# TOP_RCM_TOP_RCM_53200000h register map
Vendor: Texas Instruments
Registers are 32-bit, read-write, reset 0x0 unless marked. A register's access mark holds for its fields unless they carry their own. Offsets are as the file gives them; [hi:lo] are bit positions; {n}, {i} and the like mark numbered series.

## TOP_RCM (part 2 of 2)
0x04 TOP_RCM_SYS_RST_CAUSE ro reset 0x41 — Warm Reset Cause Register.
  [26:0] SYS_RST_CAUSE_CAUSE — Warm Reset Cause register 27'h0000041 - POR reset 27'h0000042 - Warm reset due to MSS_WDT0 27'h0000044 - Warm reset due to MSS_WDT1 27'h0000060 - Warm reset due to TOP_RMC:WARM_RESET_REQ 27'h0000040 - External Pad reset 27'h00000c0 - Warm reset due to HSM_WDT 27'h0000140 - Warm Reset due to Debugger reset 27'h0000240 - Warm Reset due to Temp Sense0 Reset 27'h0000440 - Warm Reset due to Temp Sense1 Reset 27'h0000840 - Warm Reset due to vmon_cmp1_ov 27'h0001040 - Warm Reset due to vmon_cmp2_ov 27'h0002040 - Warm Reset due to vmon_cmp3_ov 27'h0004040 - Warm Reset due to vmon_cmp5_ov 27'h0008040 - Warm Reset due to vmon_cmp0_uv 27'h0010040 - Warm Reset due to vmon_cmp1_uv 27'h0020040 - Warm Reset due to vmon_cmp2_uv 27'h0040040 - Warm Reset due to vmon_cmp3_uv 27'h0080040 - Warm Reset due to vmon_cmp5_uv 27'h0100040 - Warm Reset due to vmon_cmp7_uv 27'h0200040 - Warm Reset due to vmon_cmp8_uv 27'h0400040 - Warm Reset due to clk_loss on sys_clk 27'h0800040 - Warm Reset due to esm critical priority interrupt27'h1000040 - Warm Reset due to esm high priority watchdog interrupt27'h2000040 - Warm Reset due to esm error pin monitor interrupt 27'h4000040 - POR assert from SW
0x08 TOP_RCM_SYS_RST_CAUSE_CLR — Warm Reset Cause Register Clear.
  [2:0] SYS_RST_CAUSE_CLR_CLEAR — Write pulse bit field to 3'b111: Data should be loaded as multibit. Warm Reset Cause register Clear
0x0C TOP_RCM_WARM_RESET_REQ reset 0x7 — Warm Reset Config options.
  [2:0] WARM_RESET_REQ_SW_RST — Data should be loaded as multibit. Write 3'b000 to assert warm reset from SWWrite 3'b111 to deassert warm reset from SW if this is the only source of warm reset
0x10 TOP_RCM_WARM_RSTTIME1 reset 0x888 — programing Output delay: time between internal warm reset source assert to warm reset pad deassert.
  [11:0] WARM_RSTTIME1_DELAY — Program sufficient delay using this bitfield to keep the WARMRSTn pad active for any external devices relying on the reset signal. Refer to Reset Details Section in TRM for more details.Data should be loaded as multibit. For example: if value of 0x5 should be selected then 0x555 should be configured to the register.**Note: This bit will only be reset by PORz.
0x14 TOP_RCM_WARM_RSTTIME2 reset 0x888 — programing input Rise delay : time between warm reset pad deassert to chip warm reset deassert.
  [11:0] WARM_RSTTIME2_DELAY — Program the deassertion delay with this bitfield to control internal system reset deassertion which is relative to the deassertion of WARMRSTn pad.Data should be loaded as multibit. For example: if value of 0x5 should be selected then 0x555 should be configured to the register.**Note: This bit will only be reset by PORz.
0x18 TOP_RCM_WARM_RSTTIME3 reset 0x111 — programing Input Fall delay : time between warm reset pad assert to chip warm reset assert.
  [11:0] WARM_RSTTIME3_DELAY — The glitch filter logic will filter any input pad signal which is LOW for any time less than the delay programmed with this bit.This parameter also programmes the delay from external Warmrestn assertion to Internal system warm resetn assertion.Data should be loaded as multibit. For example: if value of 0x5 should be selected then 0x555 should be configured to the register.**Note: This bit will only be reset by PORz.
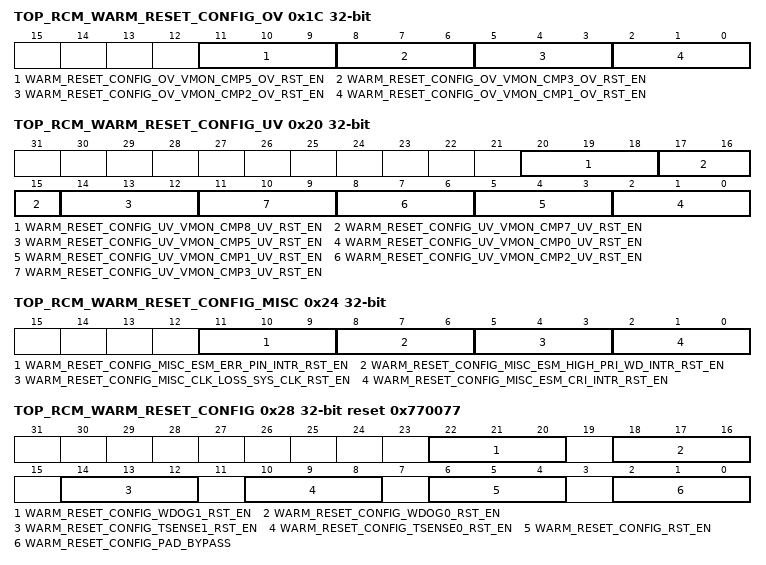
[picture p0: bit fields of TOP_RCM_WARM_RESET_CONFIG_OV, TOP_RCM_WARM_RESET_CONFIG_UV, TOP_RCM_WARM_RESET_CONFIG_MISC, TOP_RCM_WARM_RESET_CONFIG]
0x1C TOP_RCM_WARM_RESET_CONFIG_OV — VMON OverVoltage triggering Warm Reset Config.
  [11:9] WARM_RESET_CONFIG_OV_VMON_CMP5_OV_RST_EN — Enable/Disable VMON Overvoltage CMP5 triggering Warm ResetData should be loaded as multibit. Write 3'b000 to disable vmon_ov rst_en Write 3'b111 to enable vmon_ov rst_en **Note: This bit will only be reset by PORz.
  [8:6] WARM_RESET_CONFIG_OV_VMON_CMP3_OV_RST_EN — Enable/Disable VMON Overvoltage CMP3 triggering Warm ResetData should be loaded as multibit. Write 3'b000 to disable vmon_ov rst_en Write 3'b111 to enable vmon_ov rst_en **Note: This bit will only be reset by PORz.
  [5:3] WARM_RESET_CONFIG_OV_VMON_CMP2_OV_RST_EN — Enable/Disable VMON Overvoltage CMP2 triggering Warm ResetData should be loaded as multibit. Write 3'b000 to disable vmon_ov rst_en Write 3'b111 to enable vmon_ov rst_en **Note: This bit will only be reset by PORz.
  [2:0] WARM_RESET_CONFIG_OV_VMON_CMP1_OV_RST_EN — Enable/Disable VMON Overvoltage CMP1 triggering Warm ResetData should be loaded as multibit. Write 3'b000 to disable vmon_ov rst_en Write 3'b111 to enable vmon_ov rst_en**Note: This bit will only be reset by PORz.
0x20 TOP_RCM_WARM_RESET_CONFIG_UV — VMON UnderVoltage triggering Warm Reset Config.
  [20:18] WARM_RESET_CONFIG_UV_VMON_CMP8_UV_RST_EN — Enable/Disable VMON Undervoltage CMP8 triggering Warm ResetData should be loaded as multibit. Write 3'b000 to disable vmon_uv rst_en Write 3'b111 to enable vmon_uv rst_en **Note: This bit will only be reset by PORz.
  [17:15] WARM_RESET_CONFIG_UV_VMON_CMP7_UV_RST_EN — Enable/Disable VMON Undervoltage CMP7 triggering Warm ResetData should be loaded as multibit. Write 3'b000 to disable vmon_uv rst_en Write 3'b111 to enable vmon_uv rst_en **Note: This bit will only be reset by PORz.
  [14:12] WARM_RESET_CONFIG_UV_VMON_CMP5_UV_RST_EN — Enable/Disable VMON Undervoltage CMP5 triggering Warm ResetData should be loaded as multibit. Write 3'b000 to disable vmon_uv rst_en Write 3'b111 to enable vmon_uv rst_en **Note: This bit will only be reset by PORz.
  [3n+2:3n] WARM_RESET_CONFIG_UV_VMON_CMP{n}_UV_RST_EN (n=0..3) — Enable/Disable VMON Undervoltage CMP{n} triggering Warm ResetData should be loaded as multibit. Write 3'b000 to disable vmon_uv rst_en Write 3'b111 to enable vmon_uv rst_en **Note: This bit will only be reset by PORz.
0x24 TOP_RCM_WARM_RESET_CONFIG_MISC — ESM and Clk Loss on SYS_CLK triggering Warm Reset Config.
  [11:9] WARM_RESET_CONFIG_MISC_ESM_ERR_PIN_INTR_RST_EN — Enable/Disable ESM triggering Warm ResetData should be loaded as multibit. Write 3'b000 to disable esm rst_en Write 3'b111 to enable esm rst_en
  [8:6] WARM_RESET_CONFIG_MISC_ESM_HIGH_PRI_WD_INTR_RST_EN — Enable/Disable ESM triggering Warm ResetData should be loaded as multibit. Write 3'b000 to disable esm rst_en Write 3'b111 to enable esm rst_en
  [5:3] WARM_RESET_CONFIG_MISC_CLK_LOSS_SYS_CLK_RST_EN — Enable/Disable Clock loss on SYS_CLK triggering Warm ResetData should be loaded as multibit. Write 3'b000 to disable clk_loss on sys_clk rst_en Write 3'b111 to enable clk_loss on sys_clk rst_en
  [2:0] WARM_RESET_CONFIG_MISC_ESM_CRI_INTR_RST_EN — Enable/Disable ESM triggering Warm ResetData should be loaded as multibit. Write 3'b000 to disable esm rst_en Write 3'b111 to enable esm rst_en
0x28 TOP_RCM_WARM_RESET_CONFIG reset 0x770077 — Warm Reset Config options.
  [22:20] WARM_RESET_CONFIG_WDOG1_RST_EN — Enable/Disable WATCHDOG1 triggering Warm ResetData should be loaded as multibit. Write 3'b000 to disable corresponding Watchdog Write 3'b111 enable corresponding Watchdog
  [18:16] WARM_RESET_CONFIG_WDOG0_RST_EN — Enable/Disable WATCHDOG0 triggering Warm ResetData should be loaded as multibit. Write 3'b000 to disable corresponding Watchdog Write 3'b111 enable corresponding Watchdog
  [14:12] WARM_RESET_CONFIG_TSENSE1_RST_EN — Enable/Disable TEMPSENSE1 triggering Warm ResetData should be loaded as multibit. Write 3'b000 to disable temperature sensor 1 Write 3'b111 to enable temperature sensor 1 **Note: This bit will only be reset by PORz.
  [10:8] WARM_RESET_CONFIG_TSENSE0_RST_EN — Enable/Disable TEMPSENSE0 triggering Warm ResetData should be loaded as multibit. Write 3'b000 to disable temperature sensor 0 Write 3'b111 to enable temperature sensor 0 **Note: This bit will only be reset by PORz.
  [6:4] WARM_RESET_CONFIG_RST_EN — Enable/Disable DEBUGSS triggering Warm ResetData should be loaded as multibit. Write 3'b000 to disable debugger control on Warm ResetWrite 3'b111 enable debugger control on Warm Reset
  [2:0] WARM_RESET_CONFIG_PAD_BYPASS — Bypass the Warm reset from Pad InputData should be loaded as multibit. Write 3'b000 : Pad Warm Reset pin has control over warm resetWrite 3'b111 : Pad warm reset pin has no control on warm reset**Note: This bit will only be reset by PORz.
0x2C TOP_RCM_SW_POR — To trigger POR through software .
  [2:0] SW_POR_ASSERT — Software POR triggerData should be loaded as multibitWrite 3'b000: Reset is not asserted by SWWrite 3'b111: Reset is asserted by SW
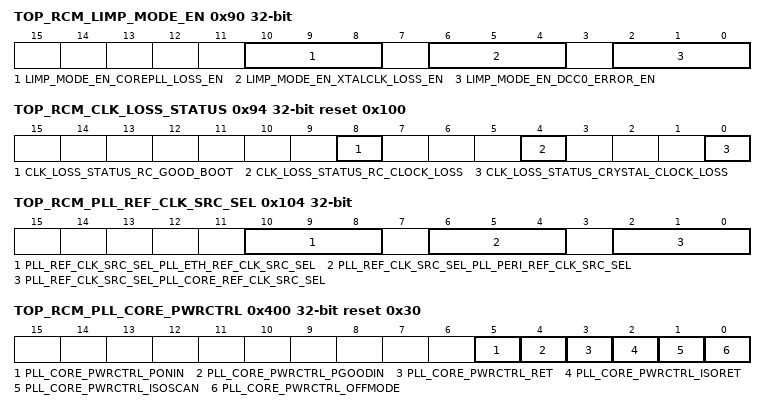
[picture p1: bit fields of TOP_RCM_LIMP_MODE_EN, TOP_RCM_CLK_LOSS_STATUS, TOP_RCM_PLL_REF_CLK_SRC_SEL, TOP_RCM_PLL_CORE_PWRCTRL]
0x90 TOP_RCM_LIMP_MODE_EN — LIMP_MODE_EN.
  [10:8] LIMP_MODE_EN_COREPLL_LOSS_EN — Enable for core pll phase lock loss to generate Limp mode3'b000: will not generate Limp mode [multibit 000]3'b111 : will generate Limp mode [multibit 111]
  [6:4] LIMP_MODE_EN_XTALCLK_LOSS_EN — Enable for crystal_clock_loss to generate Limp mode3'b000: will not generate Limp mode [multibit 000]3'b111 : will generate Limp mode [multibit 111]
  [2:0] LIMP_MODE_EN_DCC0_ERROR_EN — Enable DCC0 Error to generate Limp mode 3'b000: DCC0 Error will not generate Limp mode [multibit 000]3'b111 : DCC0 Error will generate Limp mode [multibit 111]
0x94 TOP_RCM_CLK_LOSS_STATUS ro reset 0x100 — Coarse detection clock loss status for RC and Crystal.
  [8] CLK_LOSS_STATUS_RC_GOOD_BOOT — Clock status of RC clock at boot. Reset value will reflect the actual status1 --> clock present at boot0 --> clock not present at boot
  [4] CLK_LOSS_STATUS_RC_CLOCK_LOSS — Coarse detection clock loss status for RC clock. Reset value will reflect the actual status1 --> clock lost0 --> clock good
  [0] CLK_LOSS_STATUS_CRYSTAL_CLOCK_LOSS — Coarse detection clock loss status for Crystal clock. Reset value will reflect the actual status1 --> clock lost0 --> clock good
0x100 TOP_RCM_RCOSC32K_CTRL — RCOSC32K_CTRL.
  [2:0] RCOSC32K_CTRL_STOPOSC — Stop 32KHz RCOSC. Write 3'b111 to stop clock
0x104 TOP_RCM_PLL_REF_CLK_SRC_SEL — CORE PLL and PERI PLL reference clock select.
  [10:8] PLL_REF_CLK_SRC_SEL_PLL_ETH_REF_CLK_SRC_SEL — Mux selct for PERI PLL1 REF clockWrite 3'b111 : to select external reference clock as PLL reference clockWrite 3'b000 : to select on-die clock as PLL reference clock
  [6:4] PLL_REF_CLK_SRC_SEL_PLL_PERI_REF_CLK_SRC_SEL — Mux selct for PERI PLL REF clockWrite 3'b111 : to select external reference clock as PLL reference clockWrite 3'b000 : to select on-die clock as PLL reference clock
  [2:0] PLL_REF_CLK_SRC_SEL_PLL_CORE_REF_CLK_SRC_SEL — Mux selct for CORE PLL REF clockWrite 3'b111 : to select external reference clock as PLL reference clockWrite 3'b000 : to select on-die clock as PLL reference clock
0x10C TOP_RCM_SOP_MODE_VALUE ro — SOP_MODE_VALUE.
  [31:0] SOP_MODE_VALUE_VAL — Bootmode (SOP_MODE) values and their corresponding mapping SOP3 SOP2 SOP1 SOP0 Bootmode 0 0 0 0 OSPI Functional Mode[4S] 0 0 0 1 UART Functional Mode 0 0 1 0 OSPI Functional Mode[1S] 0 0 1 1 OSPI Functional Mode[8S] 0 1 1 0 OSPI Serial NAND Functional Mode[1S] 0 1 1 1 OSPI Serial NAND Functional Mode[4S] 1 0 1 1 DevBoot mode 1 1 0 0 xSPI 8D (SFDP)mode 1 1 0 1 OSPI Serial NAND (8S) mode 1 1 1 0 USB DFU mode Any undefined values are reserved for future use.Note: Reset value of MMR is 0, but true SOP pin values will latch immediately after PORz reset is released. CPU reads to the MMR will only reflect the SOP mode values latched at reset.
0x114 TOP_RCM_VMON_CLK_GATE — VMON_CLK_GATE.
  [2:0] VMON_CLK_GATE_ENABLE — Clock gatring config for VMON clockData should be loaded as multibit. Write 3'b000 : Clock is ungated [multibit 000]Write 3'b111 : Clock is gated [multibit 111]
0x400 TOP_RCM_PLL_CORE_PWRCTRL reset 0x30 — PLL_CORE_PWRCTRL refer to PLL spec for complete functional description of the below bitfields.
  [5] PLL_CORE_PWRCTRL_PONIN — ON/OFF control of the weak power switch digital. For functionalmode it should be 1'b1
  [4] PLL_CORE_PWRCTRL_PGOODIN — ON/OFF control of the strong power switch digital. For functional mode it should be 1'b1
  [3] PLL_CORE_PWRCTRL_RET — Save/Restore control for Retention mode. For functional mode itshould be 1'b0
  [2] PLL_CORE_PWRCTRL_ISORET — Save/Restore control for Isolation of output pins For functional modeit should be 1'b0
  [1] PLL_CORE_PWRCTRL_ISOSCAN — Save/Restore control for Isolation of the Scanout pins. For functionalmode it should be 1'b0
  [0] PLL_CORE_PWRCTRL_OFFMODE — Used to switch OFF the logic on VDDA. For functional mode itshould be 1'b0
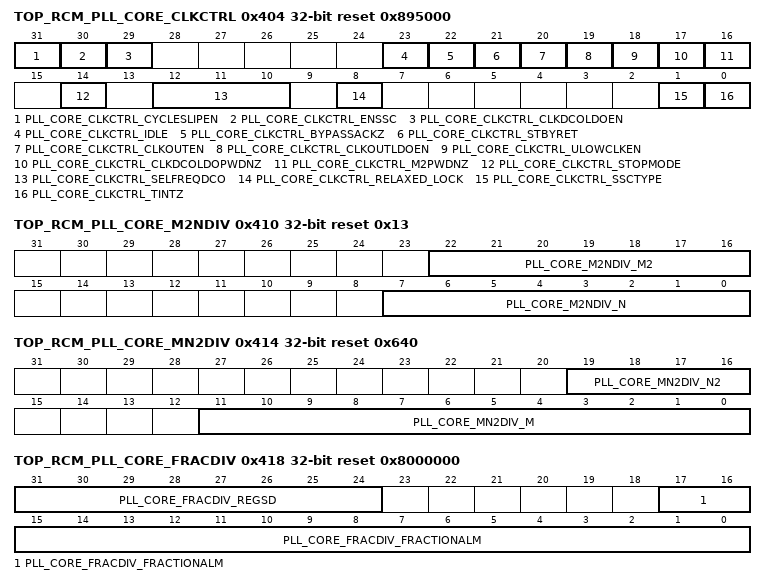
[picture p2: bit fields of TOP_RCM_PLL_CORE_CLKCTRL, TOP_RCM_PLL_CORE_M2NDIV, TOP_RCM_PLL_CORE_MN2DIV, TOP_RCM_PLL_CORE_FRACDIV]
0x404 TOP_RCM_PLL_CORE_CLKCTRL reset 0x895000 — PLL_CORE_CLKCTRL refer to PLL spec for complete functional description of the below bitfields.
  [31] PLL_CORE_CLKCTRL_CYCLESLIPEN — FailSafe enable to trigger re-calibration in case CycleSlip occurs between REFCLK and FBCLK. Cycleslip could be caused if loop is not able to track input clock. Default = 1'b0 recommended
  [30] PLL_CORE_CLKCTRL_ENSSC — Controls Clock SpReading. SSC is not supported. Should be set to 0x0 to disable clock spReading.
  [29] PLL_CORE_CLKCTRL_CLKDCOLDOEN — Synchronously enables/disables CLKDCOLDO0x0 : synchronously disables CLKDCOLDO0x1 : synchronously enables CLKDCOLDO
  [23] PLL_CORE_CLKCTRL_IDLE — Sets PLL to Idle mode0x0 : When SYSRESET = 0 and TINITZ = 1 IDLE = 0 PLL will go toActive and Locked0x1 : When SYSRESET = 0 and TINITZ = 1 IDLE = 1 PLL will go toIdle Bypass low powe
  [22] PLL_CORE_CLKCTRL_BYPASSACKZ — BYPASSACKZ is a special purpose input to the module. In generalthis input is expected to be tied to static low. For the output clocks ofthe module that do not have an internal bypass mux viz.CLKDCOLDO and CLKOUTLDO, a bypass mux could beimplemented external to the module.
  [21] PLL_CORE_CLKCTRL_STBYRET — Standby retention control0x0 : prepares ADPLLLJ for relock when out of retention byremoving the gating on all internal clocks.0x1 : prepares ADPLLLJ for retention by gating all the internalclocks.
  [20] PLL_CORE_CLKCTRL_CLKOUTEN — CLKOUT enable or disable0x0 : synchronously disables CLKOUT0x1 : synchronously enables CLKOUT
  [19] PLL_CORE_CLKCTRL_CLKOUTLDOEN — Synchronously enables/disables CLKOUTLDO 0x0 : synchronously disables CLKOUTLDO 0x1 : synchronously enables CLKOUTLDO
  [18] PLL_CORE_CLKCTRL_ULOWCLKEN — Select CLKOUT source in bypass0x0: When ADPLLLJ in bypass mode, CLKOUT = CLKINP/[N2+1]0x1: When ADPLLLJ in bypass mode, CLKOUT = CLKINPULOW.
  [17] PLL_CORE_CLKCTRL_CLKDCOLDOPWDNZ — 0 Asynchronous power down for CLKDCOLDO o/p.
  [16] PLL_CORE_CLKCTRL_M2PWDNZ — M2 divider power down mode0x0: Asynchronous power down for M2 divider0x1 : M2 divider is functional
  [14] PLL_CORE_CLKCTRL_STOPMODE — When in Lossclk/Stbyret 0x0 : Limp mode 0x1 : Stopmode
  [12:10] PLL_CORE_CLKCTRL_SELFREQDCO — DCO Clock [DCOCLK = CLKINP * [M/[N+1]]] frequency rangeselector.0x0: Reserved0x2: HS2 : DCOCLK range is from 500 MHz to1000MHz0x3: Reserved0x4: HS1: DCOCLK range is from1000MHz to2000MHz0x5: Reserved
  [8] PLL_CORE_CLKCTRL_RELAXED_LOCK — Decides when FREQLOCK asserted0x0: FREQLOCK asserted when DC frequency error less than 1%0x1: FREQLOCK asserted when DC frequency error less than 2%
  [1] PLL_CORE_CLKCTRL_SSCTYPE — SSC Type - This should be configured as 1'b0. The module supports spread spectrum clocking [SSC] on its output clocks.
  [0] PLL_CORE_CLKCTRL_TINTZ — PLL core soft reset. TINITZ activation [Low] gives softreset to ADPLLLJ. TINITZ does not reset the entire digital control logic; it forces the FSM into RESET State so that ADPLLLJ could restart.
0x408 TOP_RCM_PLL_CORE_TENABLE — PLL_CORE_TENABLE refer to PLL spec for complete functional description of the below bitfields.
  [0] PLL_CORE_TENABLE_TENABLE — Signal TENABLE loads REGM, REGN, REGSD and SELFREQDCO data. M, N. SD and SELFREQDCO latch [active rise edge]
0x40C TOP_RCM_PLL_CORE_TENABLEDIV — PLL_CORE_TENABLEDIV refer to PLL spec for complete functional description of the below bitfields.
  [0] PLL_CORE_TENABLEDIV_TENABLEDIV — TENABLEDIV rising edge loads the values of M2REG and N2REG into ADPLLLJ register. TENABLEDIV could be activated anytime when the DPLL digital is in power-up condition. M2 and N2 latch [active rise edge]
0x410 TOP_RCM_PLL_CORE_M2NDIV reset 0x13 — PLL_CORE_M2NDIV refer to PLL spec for complete functional description of the below bitfields.
  [22:16] PLL_CORE_M2NDIV_M2 — Post-divider is REGM2
  [7:0] PLL_CORE_M2NDIV_N — Pre-divider is REGN+1
0x414 TOP_RCM_PLL_CORE_MN2DIV reset 0x640 — PLL_CORE_MN2DIV refer to PLL spec for complete functional description of the below bitfields.
  [19:16] PLL_CORE_MN2DIV_N2 — Bypass divider is REGN2+1
  [11:0] PLL_CORE_MN2DIV_M — Feedback Multiplier is REGM
0x418 TOP_RCM_PLL_CORE_FRACDIV reset 0x8000000 — PLL_CORE_FRACDIV refer to PLL spec for complete functional description of the below bitfields.
  [31:24] PLL_CORE_FRACDIV_REGSD — Sigma-Delta DividerShould be set by s/w to provide optimum jitter performance.DPLL_SD_DIV = CEILING [[DPLL_MULT/[DPLL_DIV+1]] * CLKINP/ 250], where CLKINP is the input clock of the DPLL in MHz
  [17:0] PLL_CORE_FRACDIV_FRACTIONALM — Fractional part of the M divider.The 18bit FractionalM value is loaded into DPLL on the rising edge of TENABLE signal .To enable Integer only division FractionalM should be set to 18'b0.
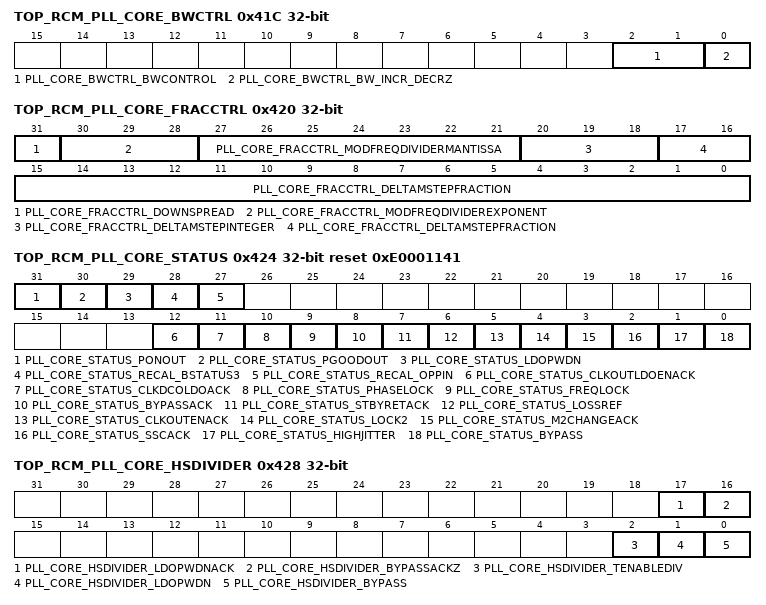
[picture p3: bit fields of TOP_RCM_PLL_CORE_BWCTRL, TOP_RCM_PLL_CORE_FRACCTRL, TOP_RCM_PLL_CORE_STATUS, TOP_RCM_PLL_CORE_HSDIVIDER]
0x41C TOP_RCM_PLL_CORE_BWCTRL — PLL_CORE_BWCTRL refer to PLL spec for complete functional description of the below bitfields.
  [2:1] PLL_CORE_BWCTRL_BWCONTROL — Change Loop Bandwidth
  [0] PLL_CORE_BWCTRL_BW_INCR_DECRZ — Direction of Loop Bandwidth0x0 : decrease BW0x1 : increase BW
0x420 TOP_RCM_PLL_CORE_FRACCTRL — PLL_CORE_FRACCTRL refer to PLL spec for complete functional description of the below bitfields.
  [31] PLL_CORE_FRACCTRL_DOWNSPREAD — Controls frequency spread0x0 : enables both side frequency spread about the programmed frequency.0x1 : enables low frequency spread only
  [30:28] PLL_CORE_FRACCTRL_MODFREQDIVIDEREXPONENT — Exponent of the REFCLK divider to define the modulation frequency.
  [27:21] PLL_CORE_FRACCTRL_MODFREQDIVIDERMANTISSA — Mantissa of the REFCLK divider to define the modulation frequency
  [20:18] PLL_CORE_FRACCTRL_DELTAMSTEPINTEGER — Integer part of Frequency Spread control
  [17:0] PLL_CORE_FRACCTRL_DELTAMSTEPFRACTION — The fraction part of Frequency Spread control
0x424 TOP_RCM_PLL_CORE_STATUS ro reset 0xE0001141 — PLL_CORE_STATUS refer to PLL spec for complete functional description of the below bitfields.
  [31] PLL_CORE_STATUS_PONOUT — Status of the weak power-switch0x0 : indicates the/OFF status of the weak power-switch in digital toSOC.0x1 : ndicates the ON status of the weak power-switch in digital toSOC.
  [30] PLL_CORE_STATUS_PGOODOUT — Status of the strong power-switch0x0 : indicates the/OFF status of the strong power-switch in digital toSOC.0x1 : ndicates the ON status of the strong power-switch in digital toSOC.
  [29] PLL_CORE_STATUS_LDOPWDN — 1'b1 indicates ADPLLLJ internal LDO is power down. VDDLDOOUT willbe un-defined in this condition
  [28] PLL_CORE_STATUS_RECAL_BSTATUS3 — Recalibration status flag. 1'b1 ADPLLLJ requires recalibration
  [27] PLL_CORE_STATUS_RECAL_OPPIN — Recalibration status flag. 1'b1 ADPLLLJ requires recalibration
  [12] PLL_CORE_STATUS_CLKOUTLDOENACK — Indicates the enable/disable condition of CLKOUTLDOEN0x0 = CLKOUTLDO gating completed0x1 = CLKOUTLDO enabling completed
  [11] PLL_CORE_STATUS_CLKDCOLDOACK — Indicates the enable/disable condition of CLKDCOLDOEN0x0 = CLKDCOLDO gating completed0x1 = CLKDCOLOD enabling completed
  [10] PLL_CORE_STATUS_PHASELOCK — Status on PHASELOCK output pin
  [9] PLL_CORE_STATUS_FREQLOCK — Status on FREQLOCK output pin
  [8] PLL_CORE_STATUS_BYPASSACK — Status of BYPASSACK output pin
  [7] PLL_CORE_STATUS_STBYRETACK — Standby and retention status0x0: indicates to SOC that all internal clocks in ADPLLLJ are activeand it is starting the relock process.0x1: indicates to SOC that all internal clocks in ADPLLLJ are gatedand it is ready for retention.
  [6] PLL_CORE_STATUS_LOSSREF — Reference input loss is indicated by 1'b0.
  [5] PLL_CORE_STATUS_CLKOUTENACK — Indicates the enable/disable condition of CLKOUTEN0x0 = CLKOUT gating completed0x1 = CLKOUT enabling completed
  [4] PLL_CORE_STATUS_LOCK2 — ADPLL internal loop lock status
  [3] PLL_CORE_STATUS_M2CHANGEACK — Acknowledge for change to M2 divider. Toggles from 1-0 or 0-1[depending on current value] once CLKOUT frequency change hascompleted.
  [2] PLL_CORE_STATUS_SSCACK — Spread Spectrum status0x0 : Spread-spectrum Clocking is disabled on output clocks0x1 : Spread-spectrum Clocking is enabled on output clocks
  [1] PLL_CORE_STATUS_HIGHJITTER — 1'b1 indicates jitter. After PHASELOCK is asserted high, theHIGHJITTER flag is asserted high if phase error between REFCLKand FBCLK greater than 24%.
  [0] PLL_CORE_STATUS_BYPASS — Bypass status signal. 1'b1 CLKOUT in bypass
0x428 TOP_RCM_PLL_CORE_HSDIVIDER access per field — PLL_CORE_HSDIVIDER refer to HSDIVIDER spec for complete functional description of the below bitfields.
  [17] PLL_CORE_HSDIVIDER_LDOPWDNACK ro — LDO Power Down Ack
  [16] PLL_CORE_HSDIVIDER_BYPASSACKZ ro — HSDIVIDER Bypass Ack
  [2] PLL_CORE_HSDIVIDER_TENABLEDIV rw — TENABLEDIV rising edge loads the values of M2REG and N2REG into ADPLLLJ register. TENABLEDIV could be activated anytime when the DPLL digital is in power-up condition. M2 and N2 latch [active rise edge]
  [1] PLL_CORE_HSDIVIDER_LDOPWDN rw — 1'b1 indicates ADPLLLJ internal LDO is power down. VDDLDOOUT willbe un-defined in this condition
  [0] PLL_CORE_HSDIVIDER_BYPASS rw — HSDIVIDER Bypass. Set it to 1'b1 to bypass the HSDIVIDER.
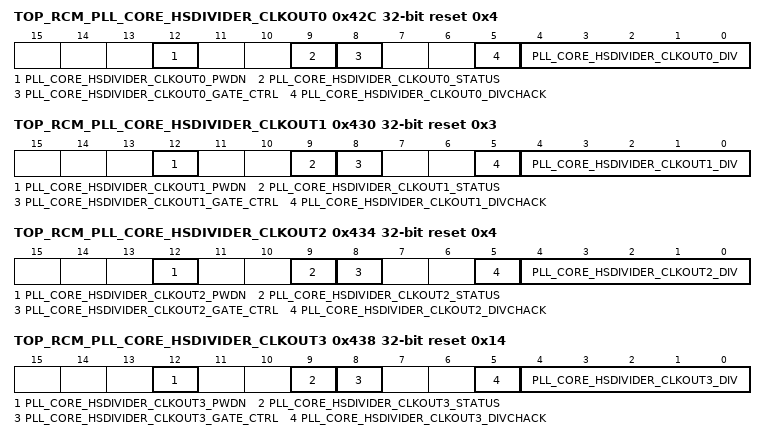
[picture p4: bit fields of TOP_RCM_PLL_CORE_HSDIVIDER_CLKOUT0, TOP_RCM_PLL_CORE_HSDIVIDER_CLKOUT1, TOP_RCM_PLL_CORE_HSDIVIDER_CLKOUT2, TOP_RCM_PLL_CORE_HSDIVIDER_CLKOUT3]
0x42C TOP_RCM_PLL_CORE_HSDIVIDER_CLKOUT0 access per field reset 0x4 — PLL_CORE_HSDIVIDER_CLKOUT0 refer to HSDIVIDER spec for complete functional description of the below bitfields.
  [12] PLL_CORE_HSDIVIDER_CLKOUT0_PWDN rw — Power down for HSDIVIDER CLKOUT0 divider and hence CLKOUT0 output0h[R/W] = CLKOUT0 divider active1h[R/W] = CLKOUT0 divider is powered down
  [9] PLL_CORE_HSDIVIDER_CLKOUT0_STATUS ro — HSDIVIDER CLKOUT0 status0h[R] = The clock output is gated1h[R] = The clock output is enabled
  [8] PLL_CORE_HSDIVIDER_CLKOUT0_GATE_CTRL rw — Control gating of HSDIVIDER CLKOUT00h[R/W] = Automatically gate this clock when there is nodependency for it1h[R/W] = Force this clock to stay enabled even if there is norequest
  [5] PLL_CORE_HSDIVIDER_CLKOUT0_DIVCHACK ro — Toggle on this status bit after changing HSDIVIDER_CLKOUT0_DIVindicates that the change in divider value has taken effect
  [4:0] PLL_CORE_HSDIVIDER_CLKOUT0_DIV rw — DPLL post-divider factor, HSDIVIDER CLKOUT0, for internal clock generation.Divide values from 1 to 31.0h[R/W] = Reserved
0x430 TOP_RCM_PLL_CORE_HSDIVIDER_CLKOUT1 access per field reset 0x3 — PLL_CORE_HSDIVIDER_CLKOUT1 refer to HSDIVIDER spec for complete functional description of the below bitfields.
  [12] PLL_CORE_HSDIVIDER_CLKOUT1_PWDN rw — Power down for HSDIVIDER CLKOUT1 divider and hence CLKOUT1 output0h[R/W] = CLKOUT1 divider active1h[R/W] = CLKOUT1 divider is powered down
  [9] PLL_CORE_HSDIVIDER_CLKOUT1_STATUS ro — HSDIVIDER CLKOUT1 status0h[R] = The clock output is gated1h[R] = The clock output is enabled
  [8] PLL_CORE_HSDIVIDER_CLKOUT1_GATE_CTRL rw — Control gating of HSDIVIDER CLKOUT10h[R/W] = Automatically gate this clock when there is nodependency for it1h[R/W] = Force this clock to stay enabled even if there is norequest
  [5] PLL_CORE_HSDIVIDER_CLKOUT1_DIVCHACK ro — Toggle on this status bit after changing HSDIVIDER_CLKOUT1_DIVindicates that the change in divider value has taken effect
  [4:0] PLL_CORE_HSDIVIDER_CLKOUT1_DIV rw — DPLL post-divider factor, HSDIVIDER CLKOUT1, for internal clock generation.Divide values from 1 to 31.0h[R/W] = Reserved
0x434 TOP_RCM_PLL_CORE_HSDIVIDER_CLKOUT2 access per field reset 0x4 — PLL_CORE_HSDIVIDER_CLKOUT2 refer to HSDIVIDER spec for complete functional description of the below bitfields.
  [12] PLL_CORE_HSDIVIDER_CLKOUT2_PWDN rw — Power down for HSDIVIDER CLKOUT2 divider and hence CLKOUT2 output0h[R/W] = CLKOUT2 divider active1h[R/W] = CLKOUT2 divider is powered down
  [9] PLL_CORE_HSDIVIDER_CLKOUT2_STATUS ro — HSDIVIDER CLKOUT2 status0h[R] = The clock output is gated1h[R] = The clock output is enabled
  [8] PLL_CORE_HSDIVIDER_CLKOUT2_GATE_CTRL rw — Control gating of HSDIVIDER CLKOUT20h[R/W] = Automatically gate this clock when there is nodependency for it1h[R/W] = Force this clock to stay enabled even if there is norequest
  [5] PLL_CORE_HSDIVIDER_CLKOUT2_DIVCHACK ro — Toggle on this status bit after changing HSDIVIDER_CLKOUT2_DIVindicates that the change in divider value has taken effect
  [4:0] PLL_CORE_HSDIVIDER_CLKOUT2_DIV rw — DPLL post-divider factor, HSDIVIDER CLKOUT2, for internal clock generation.Divide values from 1 to 31.0h[R/W] = Reserved
0x438 TOP_RCM_PLL_CORE_HSDIVIDER_CLKOUT3 access per field reset 0x14 — PLL_CORE_HSDIVIDER_CLKOUT3 refer to HSDIVIDER spec for complete functional description of the below bitfields.
  [12] PLL_CORE_HSDIVIDER_CLKOUT3_PWDN rw — Power down for HSDIVIDER CLKOUT3 divider and hence CLKOUT3 output0h[R/W] = CLKOUT3 divider active1h[R/W] = CLKOUT3 divider is powered down
  [9] PLL_CORE_HSDIVIDER_CLKOUT3_STATUS ro — HSDIVIDER CLKOUT3 status0h[R] = The clock output is gated1h[R] = The clock output is enabled
  [8] PLL_CORE_HSDIVIDER_CLKOUT3_GATE_CTRL rw — Control gating of HSDIVIDER CLKOUT30h[R/W] = Automatically gate this clock when there is nodependency for it1h[R/W] = Force this clock to stay enabled even if there is norequest
  [5] PLL_CORE_HSDIVIDER_CLKOUT3_DIVCHACK ro — Toggle on this status bit after changing HSDIVIDER_CLKOUT3_DIVindicates that the change in divider value has taken effect
  [4:0] PLL_CORE_HSDIVIDER_CLKOUT3_DIV rw — DPLL post-divider factor, M7, for internal clock generation.Divide values from 1 to 31.0h[R/W] = Reserved
0x43C TOP_RCM_PLL_CORE_RSTCTRL — PLL_CORE_RSTCTRL .
  [2:0] PLL_CORE_RSTCTRL_ASSERT — SW Reset override for the PLLWrite 3'b111 : Override is enabled and Reset is asserted
0x440 TOP_RCM_PLL_CORE_HSDIVIDER_RSTCTRL — PLL_CORE_HSDIVIDER_RSTCTRL .
  [2:0] PLL_CORE_HSDIVIDER_RSTCTRL_ASSERT — SW Reset override for the HSDIVIDERWrite 3'b111 : Override is enabled and Reset is asserted
0x500 TOP_RCM_R5SS_CLK_SRC_SEL — Clock Source select register for MSS CortexR5 clock.
  [11:0] R5SS_CLK_SRC_SEL_CLKSRCSEL — Select line for selecting source clock for MSS Coretex R5 and System bus Clock.Data should be loaded as multibit. For example: if Clock source 0x5 should be selected then 0x555 should be configured to the register.Use the following values to select clk src-0x000 - WUCPUCLK0x111 - EXT_REFCLK0x222 - DPLL_CORE_HSDIV0_CLKOUT00x333 - DPLL_ETH_HSDIV0_CLKOUT00x444 - RCCLK10M0x555 - RCCLK10M0x666 - XTALCLK0x777 - RCCLK10M
0x504 TOP_RCM_R5SS_CLK_STATUS ro reset 0x1 — Clock Status register for MSS Root clock for CortexR5 and SYS clock.
  [7:0] R5SS_CLK_STATUS_CLKINUSE — Status shows the source clock slected for Root clock for CortexR5 and Sysclk
0x510 TOP_RCM_R5SS0_CLK_DIV_SEL — Clock Divider register for Respective R5SS clock .
  [2:0] R5SS0_CLK_DIV_SEL_CLKSRCSEL — Writing 3'b000 Sets R5 clock = R5SS Root clockWriting 3'b111 Sets R5 Clock = SYSCLK
0x518 TOP_RCM_R5SS0_CLK_GATE — Clock Gating register for Respective R5SS clock.
  [2:0] R5SS0_CLK_GATE_GATED — Only for debug- Functionality not guaranteed Clock gating config for MSS Coretex R5.Data should be loaded as multibit. Write 3'b000 : Clock is ungated [multibit 000]Write 3'b111 : Clock is gated [multibit 111]
0x520 TOP_RCM_SYS_CLK_DIV_VAL — Clock Divider register for System Clock.
  [11:0] SYS_CLK_DIV_VAL_CLKDIV — Divider value for selected clock.To set the divider value of [n+1] configure the register to '0xnnn'.Data should be loaded as multibit. For example: if divider value of '0x9' is required then '0x888' should be configured to the register.
0x524 TOP_RCM_SYS_CLK_GATE — Clock Gating register for System Clock.
  [2:0] SYS_CLK_GATE_GATED — Only for debug- Functionality not guaranteed Clock gating config for System ClockData should be loaded as multibit. Write 3'b000 : Clock is ungated [multibit 000]Write 3'b111 : Clock is gated [multibit 111]
0x528 TOP_RCM_SYS_CLK_STATUS ro — Clock Status register for System Clock.
  [15:8] SYS_CLK_STATUS_CURRDIVIDER — Status shows the current divider value choosen for Sys Clock
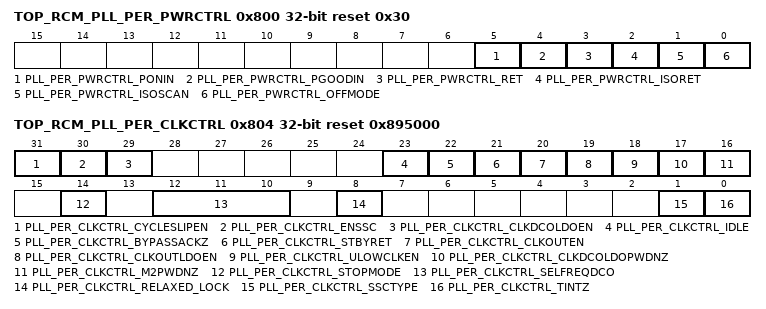
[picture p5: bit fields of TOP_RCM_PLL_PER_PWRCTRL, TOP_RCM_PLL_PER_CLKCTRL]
0x800 TOP_RCM_PLL_PER_PWRCTRL reset 0x30 — PLL_PER_PWRCTRL refer to PLL spec for complete functional description of the below bitfields.
  [5] PLL_PER_PWRCTRL_PONIN — ON/OFF control of the weak power switch digital. For functionalmode it should be 1
  [4] PLL_PER_PWRCTRL_PGOODIN — ON/OFF control of the strong power switch digital. For functional mode it should be 1
  [3] PLL_PER_PWRCTRL_RET — Save/Restore control for Retention mode. For functional mode itshould be 1'b0
  [2] PLL_PER_PWRCTRL_ISORET — Save/Restore control for Isolation of output pins For functional modeit should be 1'b0
  [1] PLL_PER_PWRCTRL_ISOSCAN — Save/Restore control for Isolation of the Scanout pins. For functionalmode it should be 1'b0
  [0] PLL_PER_PWRCTRL_OFFMODE — Used to switch OFF the logic on VDDA. For functional mode itshould be 1'b0
0x804 TOP_RCM_PLL_PER_CLKCTRL reset 0x895000 — PLL_PER_CLKCTRL refer to PLL spec for complete functional description of the below bitfields.
  [31] PLL_PER_CLKCTRL_CYCLESLIPEN — FailSafe enable to trigger re-calibration in case CycleSlip occurs between REFCLK and FBCLK. Cycleslip could be caused if loop is not able to track input clock. Default = 1'b0 recommended
  [30] PLL_PER_CLKCTRL_ENSSC — Controls Clock SpReading. SSC is not supported. Should be set to 0x0 to disable clock spReading.
  [29] PLL_PER_CLKCTRL_CLKDCOLDOEN — Synchronously enables/disables CLKDCOLDO0x0 : synchronously disables CLKDCOLDO0x1 : synchronously enables CLKDCOLDO
  [23] PLL_PER_CLKCTRL_IDLE — Sets PLL to Idle mode0x0 : When SYSRESET = 0 and TINITZ = 1 IDLE = 0 PLL will go toActive and Locked0x1 : When SYSRESET = 0 and TINITZ = 1 IDLE = 1 PLL will go toIdle Bypass low powe
  [22] PLL_PER_CLKCTRL_BYPASSACKZ — BYPASSACKZ is a special purpose input to the module. In generalthis input is expected to be tied to static low. For the output clocks ofthe module that do not have an internal bypass mux viz.CLKDCOLDO and CLKOUTLDO, a bypass mux could beimplemented external to the module.
  [21] PLL_PER_CLKCTRL_STBYRET — Standby retention control0x0 : prepares ADPLLLJ for relock when out of retention byremoving the gating on all internal clocks.0x1 : prepares ADPLLLJ for retention by gating all the internalclocks.
  [20] PLL_PER_CLKCTRL_CLKOUTEN — CLKOUT enable or disable0x0 : synchronously disables CLKOUT0x1 : synchronously enables CLKOUT
  [19] PLL_PER_CLKCTRL_CLKOUTLDOEN — Synchronously enables/disables CLKOUTLDO 0x0 : synchronously disables CLKOUTLDO 0x1 : synchronously enables CLKOUTLDO
  [18] PLL_PER_CLKCTRL_ULOWCLKEN — Select CLKOUT source in bypass0x0: When ADPLLLJ in bypass mode, CLKOUT = CLKINP/[N2+1]0x1: When ADPLLLJ in bypass mode, CLKOUT = CLKINPULOW.
  [17] PLL_PER_CLKCTRL_CLKDCOLDOPWDNZ — 0 Asynchronous power down for CLKDCOLDO o/p.
  [16] PLL_PER_CLKCTRL_M2PWDNZ — M2 divider power down mode0x0: Asynchronous power down for M2 divider0x1 : M2 divider is functional
  [14] PLL_PER_CLKCTRL_STOPMODE — When in Lossclk/Stbyret 0x0 : Limp mode 0x1 : Stopmode
  [12:10] PLL_PER_CLKCTRL_SELFREQDCO — DCO Clock [DCOCLK = CLKINP * [M/[N+1]]] frequency rangeselector.0x0: Reserved0x2: HS2 : DCOCLK range is from 500 MHz to1000MHz0x3: Reserved0x4: HS1: DCOCLK range is from1000MHz to2000MHz0x5: Reserved
  [8] PLL_PER_CLKCTRL_RELAXED_LOCK — Decides when FREQLOCK asserted0x0: FREQLOCK asserted when DC frequency error less than 1%0x1: FREQLOCK asserted when DC frequency error less than 2%
  [1] PLL_PER_CLKCTRL_SSCTYPE — SSC Type - This should be configured as 1'b0. The module supports spread spectrum clocking [SSC] on its output clocks.
  [0] PLL_PER_CLKCTRL_TINTZ — PLL core soft reset. TINITZ activation [Low] gives softreset to ADPLLLJ. TINITZ does not reset the entire digital control logic; it forces the FSM into RESET State so that ADPLLLJ could restart.
